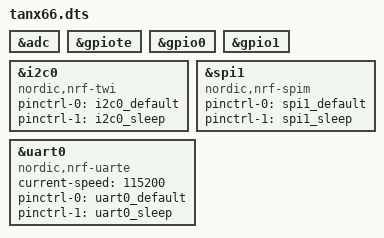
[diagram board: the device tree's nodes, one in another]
#include "tanx66-pinctrl.dtsi"

&adc {
    status = "okay";
};

&gpiote {
    status = "okay";
};

&gpio0 {
    status = "okay";
};

&gpio1 {
    status = "okay";
};

&i2c0 {
    compatible = "nordic,nrf-twi";
    pinctrl-0 = <&i2c0_default>;
    pinctrl-1 = <&i2c0_sleep>;
    pinctrl-names = "default", "sleep";
};

&spi1 {
    compatible = "nordic,nrf-spim";
    pinctrl-0 = <&spi1_default>;
    pinctrl-1 = <&spi1_sleep>;
    pinctrl-names = "default", "sleep";
};

&uart0 {
    compatible = "nordic,nrf-uarte";
    current-speed = <115200>;
    pinctrl-0 = <&uart0_default>;
    pinctrl-1 = <&uart0_sleep>;
    pinctrl-names = "default", "sleep";
};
